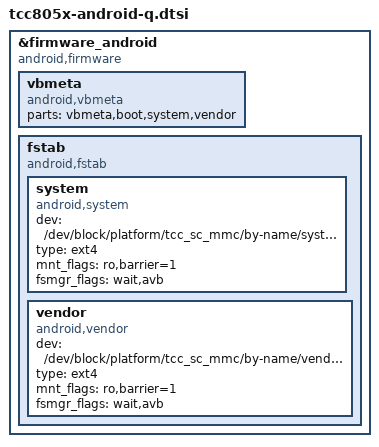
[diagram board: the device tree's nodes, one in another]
// SPDX-License-Identifier: (GPL-2.0+ OR MIT)
/*
 * Device tree for Telechips TCC803x Android platform
 *
 * Copyright (C) 2018 Telechips Inc.
 */

&firmware_android {
	compatible = "android,firmware";
	vbmeta {
		compatible = "android,vbmeta";
		parts = "vbmeta,boot,system,vendor";
	};
#if !defined(CONFIG_ANDROID_DYNAMIC_PARTITION)
	fstab {
		compatible = "android,fstab";
		system {
			compatible = "android,system";
#if !defined(CONFIG_SCSI_TCC_SC_UFS)
			dev = "/dev/block/platform/tcc_sc_mmc/by-name/system";
#else
			dev = "/dev/block/platform/tcc_sc_ufs/by-name/system";
#endif
			type = "ext4";
			mnt_flags = "ro,barrier=1";
#if !defined(CONFIG_ANDROID_AB_UPDATE)
			fsmgr_flags = "wait,avb";
#else
			fsmgr_flags = "wait,avb,slotselect";
#endif
		};
		vendor {
			compatible = "android,vendor";
#if !defined(CONFIG_SCSI_TCC_SC_UFS)
			dev = "/dev/block/platform/tcc_sc_mmc/by-name/vendor";
#else
			dev = "/dev/block/platform/tcc_sc_ufs/by-name/vendor";
#endif
			type = "ext4";
			mnt_flags = "ro,barrier=1";
#if !defined(CONFIG_ANDROID_AB_UPDATE)
			fsmgr_flags = "wait,avb";
#else
			fsmgr_flags = "wait,avb,slotselect";
#endif
		};
	};
#endif
};
